AUTOSAR XML (schema 00051)
standard types defined: uint32
package /Components
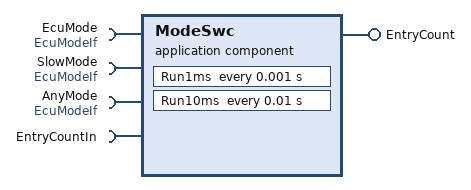
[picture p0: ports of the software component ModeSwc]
  application sw component type ModeSwc
    require port EcuMode: required-interface=EcuModeIf
    require port SlowMode: required-interface=EcuModeIf
    require port AnyMode: required-interface=EcuModeIf
    provide port EntryCount: nonqueued-sender-com-spec{data-element=EntryCount, init-value=0}, provided-interface=EntryCount
    require port EntryCountIn: nonqueued-receiver-com-spec{data-element=EntryCountIn, init-value=0}, required-interface=EntryCountIn
    behavior ModeSwc_IB
      timing event Event_Run1ms: start-on-event=Run1ms, period=0.001
      timing event Event_Run10ms: start-on-event=Run10ms, period=0.01
      4 x swc mode switch event:
        Event_OnStartupEntry: start-on-event=OnStartupEntry, activation=ON-ENTRY, mode=SlowMode.EcuMode.STARTUP
        Event_OnRunEntry: start-on-event=OnRunEntry, activation=ON-ENTRY, mode=SlowMode.EcuMode.RUN
        Event_OnRunExit: start-on-event=OnRunExit, activation=ON-EXIT, mode=SlowMode.EcuMode.RUN
        Event_OnStandbyToRun: start-on-event=OnStandbyToRun, activation=ON-TRANSITION, mode=[EcuMode.EcuMode.STANDBY, EcuMode.EcuMode.RUN]
      6 x runnable:
        Run1ms: mode-access-points=[EcuMode.EcuMode, AnyMode.EcuMode], symbol=ModeSwc_Run1ms
          data-receive-point-by-arguments:
            access IN_EntryCountIn_EntryCountIn: accessed-variable=EntryCountIn.EntryCountIn
        Run10ms: mode-access-points=[SlowMode.EcuMode, AnyMode.EcuMode], symbol=ModeSwc_Run10ms
        OnStartupEntry: mode-access-point=SlowMode.EcuMode, symbol=ModeSwc_OnStartupEntry
        OnRunEntry: mode-access-point=SlowMode.EcuMode, symbol=ModeSwc_OnRunEntry
          data-send-points:
            access OUT_EntryCount_EntryCount: accessed-variable=EntryCount.EntryCount
        OnRunExit: mode-access-point=SlowMode.EcuMode, symbol=ModeSwc_OnRunExit
        OnStandbyToRun: mode-access-point=EcuMode.EcuMode, symbol=ModeSwc_OnStandbyToRun
package /Interfaces
  mode switch interface EcuModeIf: is-service=true
    mode group EcuMode: type=EcuModes
  sender receiver interface EntryCount
    data EntryCount: type=uint32
  sender receiver interface EntryCountIn
    data EntryCountIn: type=uint32
package /ModeDeclarationGroups
  mode declaration group EcuModes: category=EXPLICIT_ORDER, initial-mode=STARTUP, on-transition-value=255
    6 x mode:
      RUN: value=10
      STARTUP: value=5
      STANDBY: value=20
      RUNDOWN: value=30
      SHUTDOWN: value=40
      SLEEP: value=50
